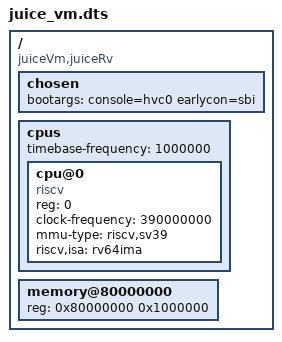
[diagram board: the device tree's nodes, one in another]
/*
 * SPDX-License-Identifier: BSD-2-Clause
 *
 * Copyright (c) 2019 Western Digital Corporation or its affiliates.
 *
 * Authors:
 *   Damien Le Moal <damien.lemoal@wdc.com>
 */

/dts-v1/;
/ {
	#address-cells = <1>;
	#size-cells = <1>;
	compatible = "juiceVm,juiceRv";

	chosen {
		bootargs = "console=hvc0 earlycon=sbi";
	};

	cpus {
		#address-cells = <1>;
		#size-cells = <0>;
		timebase-frequency = <1000000>;
		cpu@0 {
			reg = <0>;
			compatible = "riscv";
			device_type = "cpu";
			clock-frequency = <390000000>;
			mmu-type = "riscv,sv39";
			riscv,isa = "rv64ima";
			status = "okay";
		};
	};

	memory@80000000 {
		/* Bank 0: 16 MB */
		device_type = "memory";
		reg = <0x80000000 0x1000000>;
	};
};
